# CC27x0 register map
File version: 1.0
CPU: CM4 r0p4, little endian, no MPU, no FPU, VTOR, 3 interrupt priority bits
Registers are 32-bit, read-write, reset 0x0 unless marked. A register's access mark holds for its fields unless they carry their own. Offsets are from the block's base; [hi:lo] are bit positions; {n}, {i} and the like mark numbered series; 'fields as' and 'values as' point back to an identical list.

## LRFDRFE (part 1 of 2)
Base 0x40083000
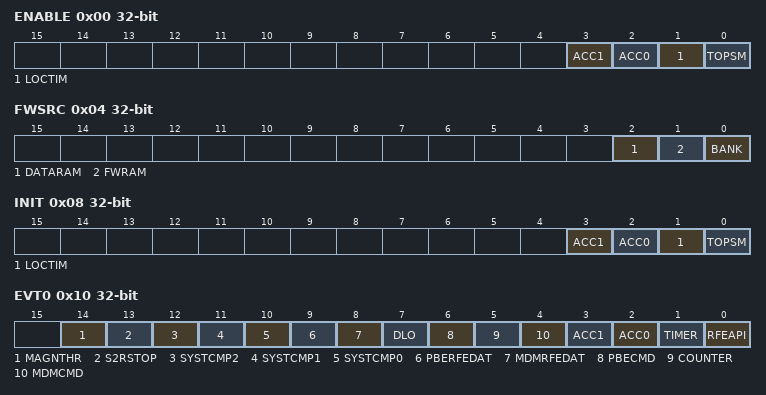
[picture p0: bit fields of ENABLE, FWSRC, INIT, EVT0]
0x00 ENABLE — Internal. Only to be used through TI provided API.
  [all] fields
    1=EN (Internal. Only to be used through TI provided API.); 0=DIS (Internal. Only to be used through TI provided API.)
  [3] ACC1 — Internal. Only to be used through TI provided API.
  [2] ACC0 — Internal. Only to be used through TI provided API.
  [1] LOCTIM — Internal. Only to be used through TI provided API.
  [0] TOPSM — Internal. Only to be used through TI provided API.
0x04 FWSRC — Internal. Only to be used through TI provided API.
  [2] DATARAM — Internal. Only to be used through TI provided API.
    1=S2RRAM (Internal. Only to be used through TI provided API.); 0=RFERAM (Internal. Only to be used through TI provided API.)
  [1] FWRAM — Internal. Only to be used through TI provided API.
    values as DATARAM
  [0] BANK — Internal. Only to be used through TI provided API.
    1=ONE (Internal. Only to be used through TI provided API.); 0=ZERO (Internal. Only to be used through TI provided API.)
0x08 INIT wo — Internal. Only to be used through TI provided API.
  [all] fields
    1=RESET (Internal. Only to be used through TI provided API.); 0=NO_EFFECT (Internal. Only to be used through TI provided API.)
  [3] ACC1 — Internal. Only to be used through TI provided API.
  [2] ACC0 — Internal. Only to be used through TI provided API.
  [1] LOCTIM — Internal. Only to be used through TI provided API.
  [0] TOPSM — Internal. Only to be used through TI provided API.
0x0C PDREQ — Internal. Only to be used through TI provided API.
  [0] TOPSMPDREQ
    values as FWSRC.BANK
0x10 EVT0 ro — Internal. Only to be used through TI provided API.
  [all] fields
    values as FWSRC.BANK
  [14] MAGNTHR — Internal. Only to be used through TI provided API.
  [13] S2RSTOP — Internal. Only to be used through TI provided API.
  [12] SYSTCMP2 — Internal. Only to be used through TI provided API.
  [11] SYSTCMP1 — Internal. Only to be used through TI provided API.
  [10] SYSTCMP0 — Internal. Only to be used through TI provided API.
  [9] PBERFEDAT — Internal. Only to be used through TI provided API.
  [8] MDMRFEDAT — Internal. Only to be used through TI provided API.
  [7] DLO — Internal. Only to be used through TI provided API.
  [6] PBECMD — Internal. Only to be used through TI provided API.
  [5] COUNTER — Internal. Only to be used through TI provided API.
  [4] MDMCMD — Internal. Only to be used through TI provided API.
  [3] ACC1 — Internal. Only to be used through TI provided API.
  [2] ACC0 — Internal. Only to be used through TI provided API.
  [1] TIMER — Internal. Only to be used through TI provided API.
  [0] RFEAPI — Internal. Only to be used through TI provided API.
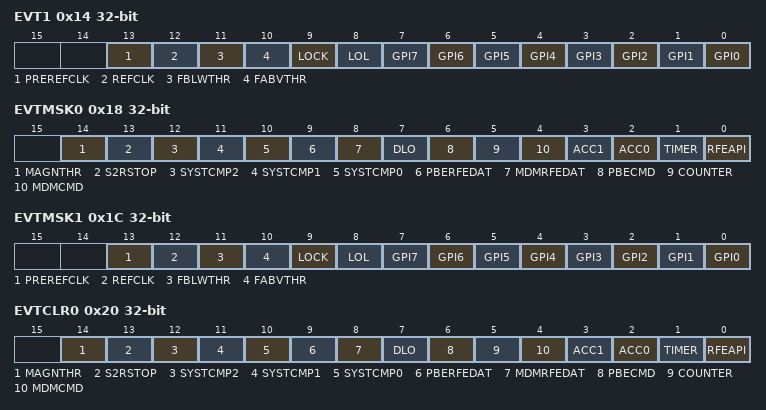
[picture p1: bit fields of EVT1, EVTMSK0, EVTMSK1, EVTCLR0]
0x14 EVT1 ro — Internal. Only to be used through TI provided API.
  [all] fields
    values as FWSRC.BANK
  [13] PREREFCLK — Internal. Only to be used through TI provided API.
  [12] REFCLK — Internal. Only to be used through TI provided API.
  [11] FBLWTHR — Internal. Only to be used through TI provided API.
  [10] FABVTHR — Internal. Only to be used through TI provided API.
  [9] LOCK — Internal. Only to be used through TI provided API.
  [8] LOL — Internal. Only to be used through TI provided API.
  [n] GPI{n} (n=0..7) — Internal. Only to be used through TI provided API.
0x18 EVTMSK0 — Internal. Only to be used through TI provided API.
  [all] fields
    values as the fields of ENABLE
  [14] MAGNTHR — Internal. Only to be used through TI provided API.
  [13] S2RSTOP — Internal. Only to be used through TI provided API.
  [12] SYSTCMP2 — Internal. Only to be used through TI provided API.
  [11] SYSTCMP1 — Internal. Only to be used through TI provided API.
  [10] SYSTCMP0 — Internal. Only to be used through TI provided API.
  [9] PBERFEDAT — Internal. Only to be used through TI provided API.
  [8] MDMRFEDAT — Internal. Only to be used through TI provided API.
  [7] DLO — Internal. Only to be used through TI provided API.
  [6] PBECMD — Internal. Only to be used through TI provided API.
  [5] COUNTER — Internal. Only to be used through TI provided API.
  [4] MDMCMD — Internal. Only to be used through TI provided API.
  [3] ACC1 — Internal. Only to be used through TI provided API.
  [2] ACC0 — Internal. Only to be used through TI provided API.
  [1] TIMER — Internal. Only to be used through TI provided API.
  [0] RFEAPI — Internal. Only to be used through TI provided API.
0x1C EVTMSK1 — Internal. Only to be used through TI provided API.
  [all] fields
    values as the fields of ENABLE
  [13] PREREFCLK — Internal. Only to be used through TI provided API.
  [12] REFCLK — Internal. Only to be used through TI provided API.
  [11] FBLWTHR — Internal. Only to be used through TI provided API.
  [10] FABVTHR — Internal. Only to be used through TI provided API.
  [9] LOCK — Internal. Only to be used through TI provided API.
  [8] LOL — Internal. Only to be used through TI provided API.
  [n] GPI{n} (n=0..7) — Internal. Only to be used through TI provided API.
0x20 EVTCLR0 wo — Internal. Only to be used through TI provided API.
  fields as EVT0
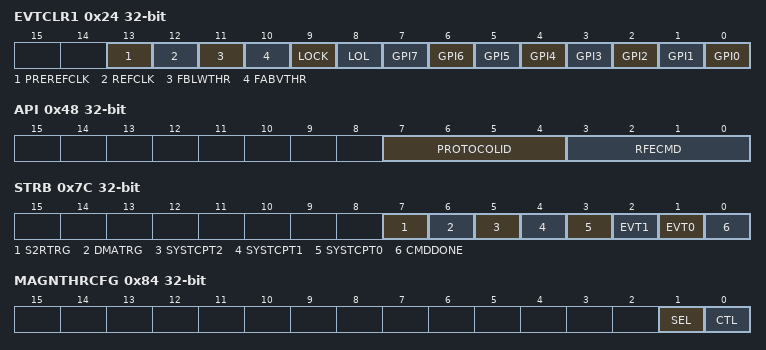
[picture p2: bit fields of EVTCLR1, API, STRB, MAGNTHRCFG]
0x24 EVTCLR1 wo — Internal. Only to be used through TI provided API.
  fields as EVT1
0x28 HFXTSTAT ro — Internal. Only to be used through TI provided API.
  [0] STAT
    1=QUAL (Internal. Only to be used through TI provided API.); 0=NONQUAL (Internal. Only to be used through TI provided API.)
0x30 RFSTATE — Internal. Only to be used through TI provided API.
  [3:0] VAL
    3=RX (Internal. Only to be used through TI provided API.); 2=TX (Internal. Only to be used through TI provided API.); 1=SYNTH (Internal. Only to be used through TI provided API.); 0=IDLE (Internal. Only to be used through TI provided API.)
0x38 SPIN ro reset 0xFF — Internal. Only to be used through TI provided API.
  [7:0] OPT
    255=ALLONES (Internal. Only to be used through TI provided API.); 0=ALLZEROS (Internal. Only to be used through TI provided API.)
0x48 API ro — Internal. Only to be used through TI provided API.
  [7:4] PROTOCOLID — Internal. Only to be used through TI provided API.
    15=ALLONES (Internal. Only to be used through TI provided API.); 0=ALLZEROS (Internal. Only to be used through TI provided API.)
  [3:0] RFECMD — Internal. Only to be used through TI provided API.
    values as PROTOCOLID
0x4C CMDPAR0 ro — Internal. Only to be used through TI provided API.
  [15:0] VAL
    0xFFFF=ALLONES (Internal. Only to be used through TI provided API.); 0=ALLZEROS (Internal. Only to be used through TI provided API.)
0x50 CMDPAR1 ro — Internal. Only to be used through TI provided API.
  fields as CMDPAR0
0x54 MSGBOX — Internal. Only to be used through TI provided API.
  [7:0] VAL
    values as SPIN.OPT
0x58 MCEDATOUT0 — Internal. Only to be used through TI provided API.
  fields as CMDPAR0
0x5C MCEDATIN0 ro — Internal. Only to be used through TI provided API.
  fields as CMDPAR0
0x60 MCECMDOUT — Internal. Only to be used through TI provided API.
  [3:0] VAL
    values as API.PROTOCOLID
0x64 MCECMDIN ro — Internal. Only to be used through TI provided API.
  fields as MCECMDOUT
0x68 PBEDATOUT1 — Internal. Only to be used through TI provided API.
  fields as CMDPAR0
0x6C PBEDATOUT0 — Internal. Only to be used through TI provided API.
  fields as CMDPAR0
0x70 PBEDATIN0 ro — Internal. Only to be used through TI provided API.
  fields as CMDPAR0
0x74 PBECMDOUT — Internal. Only to be used through TI provided API.
  fields as MCECMDOUT
0x78 PBECMDIN ro — Internal. Only to be used through TI provided API.
  fields as MCECMDOUT
0x7C STRB wo — Internal. Only to be used through TI provided API.
  [7] S2RTRG — Internal. Only to be used through TI provided API.
    values as FWSRC.BANK
  [6] DMATRG — Internal. Only to be used through TI provided API.
    values as FWSRC.BANK
  [5] SYSTCPT2 — Internal. Only to be used through TI provided API.
    values as FWSRC.BANK
  [4] SYSTCPT1 — Internal. Only to be used through TI provided API.
    values as FWSRC.BANK
  [3] SYSTCPT0 — Internal. Only to be used through TI provided API.
    values as FWSRC.BANK
  [2] EVT1 — Internal. Only to be used through TI provided API.
    values as FWSRC.BANK
  [1] EVT0 — Internal. Only to be used through TI provided API.
    values as FWSRC.BANK
  [0] CMDDONE — Internal. Only to be used through TI provided API.
    1=YES (Internal. Only to be used through TI provided API.); 0=NO (Internal. Only to be used through TI provided API.)
0x84 MAGNTHRCFG — Internal. Only to be used through TI provided API.
  [1] SEL — Internal. Only to be used through TI provided API.
    1=MAGNACC1 (Internal. Only to be used through TI provided API.); 0=MAGNACC0 (Internal. Only to be used through TI provided API.)
  [0] CTL — Internal. Only to be used through TI provided API.
    values as the fields of ENABLE
0x88 MAGNTHR — Internal. Only to be used through TI provided API.
  fields as MSGBOX
0x8C RSSIOFFSET — Internal. Only to be used through TI provided API.
  fields as MSGBOX
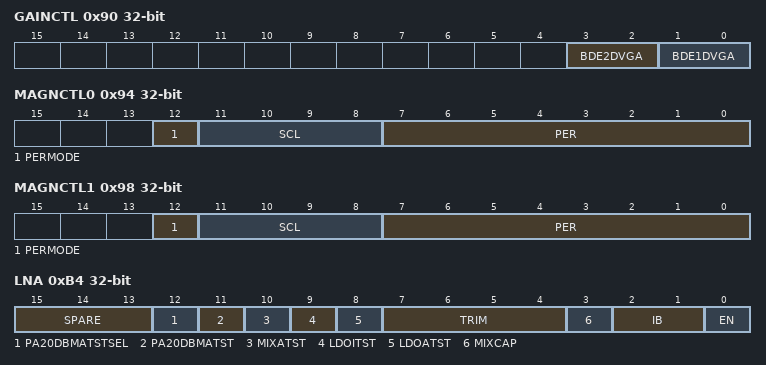
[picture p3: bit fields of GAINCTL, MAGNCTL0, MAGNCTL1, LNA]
0x90 GAINCTL — Internal. Only to be used through TI provided API.
  [3:2] BDE2DVGA — Internal. Only to be used through TI provided API.
    3=GAIN8 (Internal. Only to be used through TI provided API.); 2=GAIN4 (Internal. Only to be used through TI provided API.); 1=GAIN2 (Internal. Only to be used through TI provided API.); 0=GAIN1 (Internal. Only to be used through TI provided API.)
  [1:0] BDE1DVGA — Internal. Only to be used through TI provided API.
    values as BDE2DVGA
0x94 MAGNCTL0 — Internal. Only to be used through TI provided API.
  [12] PERMODE — Internal. Only to be used through TI provided API.
    1=PERIODIC (Internal. Only to be used through TI provided API.); 0=ONESHOT (Internal. Only to be used through TI provided API.)
  [11:8] SCL — Internal. Only to be used through TI provided API.
    8=DIV256 (Internal. Only to be used through TI provided API.); 7=DIV128 (Internal. Only to be used through TI provided API.); 6=DIV64 (Internal. Only to be used through TI provided API.); 5=DIV32 (Internal. Only to be used through TI provided API.); 4=DIV16 (Internal. Only to be used through TI provided API.); 3=DIV8 (Internal. Only to be used through TI provided API.); 2=DIV4 (Internal. Only to be used through TI provided API.); 1=DIV2 (Internal. Only to be used through TI provided API.); 0=DIV1 (Internal. Only to be used through TI provided API.)
  [7:0] PER — Internal. Only to be used through TI provided API.
    values as SPIN.OPT
0x98 MAGNCTL1 — Internal. Only to be used through TI provided API.
  fields as MAGNCTL0
{0x9C+4i} SPARE{i} (i=0..5) — Internal. Only to be used through TI provided API.
  fields as CMDPAR0
0xB4 LNA — Internal. Only to be used through TI provided API.
  [15:13] SPARE — Internal. Only to be used through TI provided API.
    values as the fields of ENABLE
  [12] PA20DBMATSTSEL — Internal. Only to be used through TI provided API.
    1=SECOND (Internal. Only to be used through TI provided API.); 0=FIRST (Internal. Only to be used through TI provided API.)
  [11] PA20DBMATST — Internal. Only to be used through TI provided API.
    values as the fields of ENABLE
  [10] MIXATST — Internal. Only to be used through TI provided API.
    values as the fields of ENABLE
  [9] LDOITST — Internal. Only to be used through TI provided API.
    values as the fields of ENABLE
  [8] LDOATST — Internal. Only to be used through TI provided API.
    values as the fields of ENABLE
  [7:4] TRIM — Internal. Only to be used through TI provided API.
    15=ONES (Internal. Only to be used through TI provided API.); 0=ZEROS (Internal. Only to be used through TI provided API.)
  [3] MIXCAP — Internal. Only to be used through TI provided API.
    values as the fields of ENABLE
  [2:1] IB — Internal. Only to be used through TI provided API.
    3=MAX (Internal. Only to be used through TI provided API.); 0=MIN (Internal. Only to be used through TI provided API.)
  [0] EN — Internal. Only to be used through TI provided API.
    1=ON (Internal. Only to be used through TI provided API.); 0=OFF (Internal. Only to be used through TI provided API.)
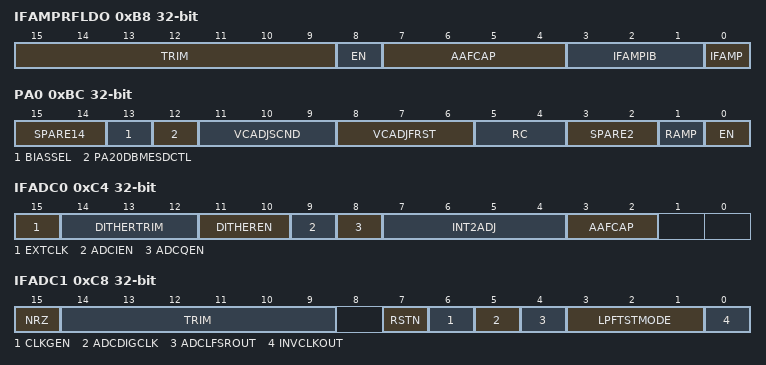
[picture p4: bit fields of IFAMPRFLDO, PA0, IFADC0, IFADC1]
0xB8 IFAMPRFLDO — Internal. Only to be used through TI provided API.
  [15:9] TRIM — Internal. Only to be used through TI provided API.
    127=BYPASS (Internal. Only to be used through TI provided API.); 126=MAX (Internal. Only to be used through TI provided API.); 0=MIN (Internal. Only to be used through TI provided API.)
  [8] EN — Internal. Only to be used through TI provided API.
    values as the fields of ENABLE
  [7:4] AAFCAP — Internal. Only to be used through TI provided API.
    15=MAX (Internal. Only to be used through TI provided API.); 0=MIN (Internal. Only to be used through TI provided API.)
  [3:1] IFAMPIB — Internal. Only to be used through TI provided API.
    7=MAX (Internal. Only to be used through TI provided API.); 0=MIN (Internal. Only to be used through TI provided API.)
  [0] IFAMP — Internal. Only to be used through TI provided API.
    values as the fields of ENABLE
0xBC PA0 — Internal. Only to be used through TI provided API.
  [15:14] SPARE14 — Internal. Only to be used through TI provided API.
    values as LNA.IB
  [13] BIASSEL — Internal. Only to be used through TI provided API.
    values as FWSRC.BANK
  [12] PA20DBMESDCTL — Internal. Only to be used through TI provided API.
    values as FWSRC.BANK
  [11:9] VCADJSCND — Internal. Only to be used through TI provided API.
    values as IFAMPRFLDO.IFAMPIB
  [8:6] VCADJFRST — Internal. Only to be used through TI provided API.
    values as IFAMPRFLDO.IFAMPIB
  [5:4] RC — Internal. Only to be used through TI provided API.
    values as LNA.IB
  [3:2] SPARE2 — Internal. Only to be used through TI provided API.
    values as LNA.IB
  [1] RAMP — Internal. Only to be used through TI provided API.
    1=UP (Internal. Only to be used through TI provided API.); 0=DOWN (Internal. Only to be used through TI provided API.)
  [0] EN — Internal. Only to be used through TI provided API.
    values as the fields of ENABLE
0xC0 ULNA — Internal. Only to be used through TI provided API.
  [15:0] SPARE
    values as CMDPAR0.VAL
0xC4 IFADC0 — Internal. Only to be used through TI provided API.
  [15] EXTCLK — Internal. Only to be used through TI provided API.
    values as the fields of ENABLE
  [14:12] DITHERTRIM — Internal. Only to be used through TI provided API.
    7=ONES (Internal. Only to be used through TI provided API.); 0=ZEROS (Internal. Only to be used through TI provided API.)
  [11:10] DITHEREN — Internal. Only to be used through TI provided API.
    3=ENG (Internal. Only to be used through TI provided API.); 2=ENSD (Internal. Only to be used through TI provided API.); 1=ENS (Internal. Only to be used through TI provided API.); 0=DIS (Internal. Only to be used through TI provided API.)
  [9] ADCIEN — Internal. Only to be used through TI provided API.
    values as the fields of ENABLE
  [8] ADCQEN — Internal. Only to be used through TI provided API.
    values as the fields of ENABLE
  [7:4] INT2ADJ — Internal. Only to be used through TI provided API.
    values as LNA.TRIM
  [3:2] AAFCAP — Internal. Only to be used through TI provided API.
    values as DITHEREN
0xC8 IFADC1 — Internal. Only to be used through TI provided API.
  [15] NRZ — Internal. Only to be used through TI provided API.
    values as the fields of ENABLE
  [14:9] TRIM — Internal. Only to be used through TI provided API.
    63=ONES (Internal. Only to be used through TI provided API.); 0=ZEROS (Internal. Only to be used through TI provided API.)
  [7] RSTN — Internal. Only to be used through TI provided API.
    1=DIS (Internal. Only to be used through TI provided API.); 0=EN (Internal. Only to be used through TI provided API.)
  [6] CLKGEN — Internal. Only to be used through TI provided API.
    values as the fields of ENABLE
  [5] ADCDIGCLK — Internal. Only to be used through TI provided API.
    values as the fields of ENABLE
  [4] ADCLFSROUT — Internal. Only to be used through TI provided API.
    values as the fields of ENABLE
  [3:1] LPFTSTMODE — Internal. Only to be used through TI provided API.
    values as the fields of ENABLE
  [0] INVCLKOUT — Internal. Only to be used through TI provided API.
    values as the fields of ENABLE
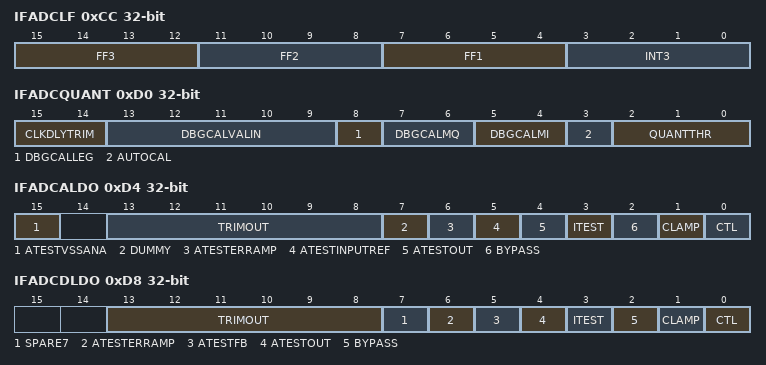
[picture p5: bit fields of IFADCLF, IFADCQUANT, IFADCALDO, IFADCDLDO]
0xCC IFADCLF — Internal. Only to be used through TI provided API.
  [all] fields
    values as LNA.TRIM
  [15:12] FF3 — Internal. Only to be used through TI provided API.
  [11:8] FF2 — Internal. Only to be used through TI provided API.
  [7:4] FF1 — Internal. Only to be used through TI provided API.
  [3:0] INT3 — Internal. Only to be used through TI provided API.
0xD0 IFADCQUANT — Internal. Only to be used through TI provided API.
  [15:14] CLKDLYTRIM — Internal. Only to be used through TI provided API.
    3=ONES (Internal. Only to be used through TI provided API.); 0=ZEROS (Internal. Only to be used through TI provided API.)
  [13:9] DBGCALVALIN — Internal. Only to be used through TI provided API.
    31=ONES (Internal. Only to be used through TI provided API.); 0=ZEROS (Internal. Only to be used through TI provided API.)
  [8] DBGCALLEG — Internal. Only to be used through TI provided API.
    1=NEG (Internal. Only to be used through TI provided API.); 0=POS (Internal. Only to be used through TI provided API.)
  [7:6] DBGCALMQ — Internal. Only to be used through TI provided API.
    3=DBGCAL_QMODB (Internal. Only to be used through TI provided API.); 2=DBGCAL_QMODP (Internal. Only to be used through TI provided API.); 1=DBGCAL_QMODN (Internal. Only to be used through TI provided API.); 0=DBGCAL_QMODZ (Internal. Only to be used through TI provided API.)
  [5:4] DBGCALMI — Internal. Only to be used through TI provided API.
    3=DBGCAL_IMODB (Internal. Only to be used through TI provided API.); 2=DBGCAL_IMODP (Internal. Only to be used through TI provided API.); 1=DBGCAL_IMODN (Internal. Only to be used through TI provided API.); 0=DBGCAL_IMODZ (Internal. Only to be used through TI provided API.)
  [3] AUTOCAL — Internal. Only to be used through TI provided API.
    values as the fields of ENABLE
  [2:0] QUANTTHR — Internal. Only to be used through TI provided API.
    values as IFADC0.DITHERTRIM
0xD4 IFADCALDO — Internal. Only to be used through TI provided API.
  [15] ATESTVSSANA — Internal. Only to be used through TI provided API.
    values as the fields of ENABLE
  [13:8] TRIMOUT — Internal. Only to be used through TI provided API.
    values as IFADC1.TRIM
  [7] DUMMY — Internal. Only to be used through TI provided API.
    1=DISN (Internal. Only to be used through TI provided API.); 0=ENN (Internal. Only to be used through TI provided API.)
  [6] ATESTERRAMP — Internal. Only to be used through TI provided API.
    values as the fields of ENABLE
  [5] ATESTINPUTREF — Internal. Only to be used through TI provided API.
    values as the fields of ENABLE
  [4] ATESTOUT — Internal. Only to be used through TI provided API.
    values as the fields of ENABLE
  [3] ITEST — Internal. Only to be used through TI provided API.
    values as the fields of ENABLE
  [2] BYPASS — Internal. Only to be used through TI provided API.
    values as the fields of ENABLE
  [1] CLAMP — Internal. Only to be used through TI provided API.
    values as the fields of ENABLE
  [0] CTL — Internal. Only to be used through TI provided API.
    values as the fields of ENABLE
0xD8 IFADCDLDO — Internal. Only to be used through TI provided API.
  [13:8] TRIMOUT — Internal. Only to be used through TI provided API.
    values as IFADC1.TRIM
  [7] SPARE7 — Internal. Only to be used through TI provided API.
    1=One (Internal. Only to be used through TI provided API.); 0=ZERO (Internal. Only to be used through TI provided API.)
  [6] ATESTERRAMP — Internal. Only to be used through TI provided API.
    values as the fields of ENABLE
  [5] ATESTFB — Internal. Only to be used through TI provided API.
    values as the fields of ENABLE
  [4] ATESTOUT — Internal. Only to be used through TI provided API.
    values as the fields of ENABLE
  [3] ITEST — Internal. Only to be used through TI provided API.
    values as the fields of ENABLE
  [2] BYPASS — Internal. Only to be used through TI provided API.
    values as the fields of ENABLE
  [1] CLAMP — Internal. Only to be used through TI provided API.
    values as the fields of ENABLE
  [0] CTL — Internal. Only to be used through TI provided API.
    values as the fields of ENABLE
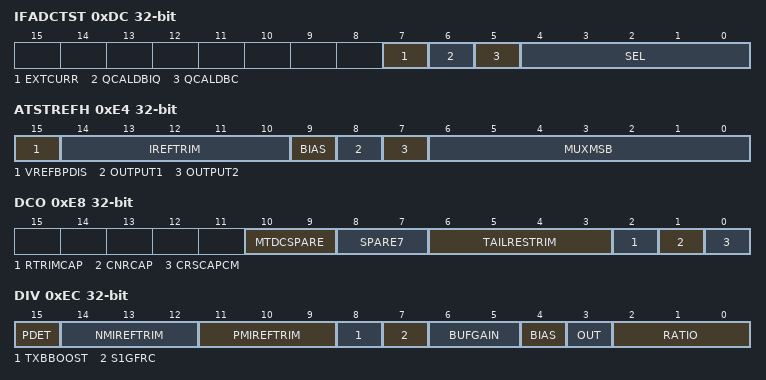
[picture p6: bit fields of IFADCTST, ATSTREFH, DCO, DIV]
0xDC IFADCTST — Internal. Only to be used through TI provided API.
  [7] EXTCURR — Internal. Only to be used through TI provided API.
    values as the fields of ENABLE
  [6] QCALDBIQ — Internal. Only to be used through TI provided API.
    1=COMP1 (Internal. Only to be used through TI provided API.); 0=COMP0 (Internal. Only to be used through TI provided API.)
  [5] QCALDBC — Internal. Only to be used through TI provided API.
    values as QCALDBIQ
  [4:0] SEL — Internal. Only to be used through TI provided API.
    31=EXTCLKN1 (Internal. Only to be used through TI provided API.); 0=NONE (Internal. Only to be used through TI provided API.)
0xE0 ATSTREFL — Internal. Only to be used through TI provided API.
  [15:0] MUXLSB
    0x8000=IFADC_ATB (Internal. Only to be used through TI provided API.); 0x4000=LDO_VTEST (Internal. Only to be used through TI provided API.); 0x2000=LDO_ITEST (Internal. Only to be used through TI provided API.); 0x800=PA_PEAK_OUTN (Internal. Only to be used through TI provided API.); 0x400=PA_PEAK_OUTP (Internal. Only to be used through TI provided API.); 0x200=MIX_OUTQN (Internal. Only to be used through TI provided API.); 0x100=MIX_OUTQP (Internal. Only to be used through TI provided API.); 128=MIX_OUTIN (Internal. Only to be used through TI provided API.); 64=MIX_OUTIP (Internal. Only to be used through TI provided API.); 32=FE_OUTIN_2 (Internal. Only to be used through TI provided API.); 16=FE_OUTIP_2 (Internal. Only to be used through TI provided API.); 8=FE_OUTQN (Internal. Only to be used through TI provided API.); 4=FE_OUTQP (Internal. Only to be used through TI provided API.); 2=FE_OUTIN (Internal. Only to be used through TI provided API.); 1=FE_OUTIP (Internal. Only to be used through TI provided API.); 0=DIS (Internal. Only to be used through TI provided API.)
0xE4 ATSTREFH — Internal. Only to be used through TI provided API.
  [15] VREFBPDIS — Internal. Only to be used through TI provided API.
    1=BPDIS (Internal. Only to be used through TI provided API.); 0=BPEN (Internal. Only to be used through TI provided API.)
  [14:10] IREFTRIM — Internal. Only to be used through TI provided API.
    values as IFADCQUANT.DBGCALVALIN
  [9] BIAS — Internal. Only to be used through TI provided API.
    values as the fields of ENABLE
  [8] OUTPUT1 — Internal. Only to be used through TI provided API.
    values as the fields of ENABLE
  [7] OUTPUT2 — Internal. Only to be used through TI provided API.
    values as the fields of ENABLE
  [6:0] MUXMSB — Internal. Only to be used through TI provided API.
    16=DIVBUF_NMOS_BIAS (Internal. Only to be used through TI provided API.); 8=DIVBUF_PMOS_BIAS (Internal. Only to be used through TI provided API.); 4=REFSYS_IREF (Internal. Only to be used through TI provided API.); 1=IFADC_ATB (Internal. Only to be used through TI provided API.); 0=DIS (Internal. Only to be used through TI provided API.)
0xE8 DCO — Internal. Only to be used through TI provided API.
  [10:9] MTDCSPARE — Internal. Only to be used through TI provided API.
    values as IFADC1.RSTN
  [8:7] SPARE7 — Internal. Only to be used through TI provided API.
    values as FWSRC.BANK
  [6:3] TAILRESTRIM — Internal. Only to be used through TI provided API.
    values as API.PROTOCOLID
  [2] RTRIMCAP — Internal. Only to be used through TI provided API.
    values as the fields of ENABLE
  [1] CNRCAP — Internal. Only to be used through TI provided API.
    1=_50MHZ (Internal. Only to be used through TI provided API.); 0=DEFAULT (Internal. Only to be used through TI provided API.)
  [0] CRSCAPCM — Internal. Only to be used through TI provided API.
    1=REDUCED (Internal. Only to be used through TI provided API.); 0=DEFAULT (Internal. Only to be used through TI provided API.)
0xEC DIV — Internal. Only to be used through TI provided API.
  [15] PDET — Internal. Only to be used through TI provided API.
    values as the fields of ENABLE
  [14:12] NMIREFTRIM — Internal. Only to be used through TI provided API.
    7=ALLONES (Internal. Only to be used through TI provided API.); 0=ALLZEROS (Internal. Only to be used through TI provided API.)
  [11:9] PMIREFTRIM — Internal. Only to be used through TI provided API.
    values as NMIREFTRIM
  [8] TXBBOOST — Internal. Only to be used through TI provided API.
    1=INCREASED (Internal. Only to be used through TI provided API.); 0=DEFAULT (Internal. Only to be used through TI provided API.)
  [7] S1GFRC — Internal. Only to be used through TI provided API.
    values as the fields of ENABLE
  [6:5] BUFGAIN — Internal. Only to be used through TI provided API.
    3=_60_PST (Internal. Only to be used through TI provided API.); 2=DONT_USE (Internal. Only to be used through TI provided API.); 1=_80_PST (Internal. Only to be used through TI provided API.); 0=MAX (Internal. Only to be used through TI provided API.)
  [4] BIAS — Internal. Only to be used through TI provided API.
    1=DEFAULT (Internal. Only to be used through TI provided API.); 0=ALTERNATIVE (Internal. Only to be used through TI provided API.)
  [3] OUT — Internal. Only to be used through TI provided API.
    1=FE_2G4 (Internal. Only to be used through TI provided API.); 0=FE_S1G (Internal. Only to be used through TI provided API.)
  [2:0] RATIO — Internal. Only to be used through TI provided API.
    7=DIV30 (Internal. Only to be used through TI provided API.); 6=DIV15 (Internal. Only to be used through TI provided API.); 5=DIV10 (Internal. Only to be used through TI provided API.); 4=DIV5 (Internal. Only to be used through TI provided API.); 3=DIV12 (Internal. Only to be used through TI provided API.); 2=DIV6 (Internal. Only to be used through TI provided API.); 1=DIV4 (Internal. Only to be used through TI provided API.); 0=DIV2 (Internal. Only to be used through TI provided API.)
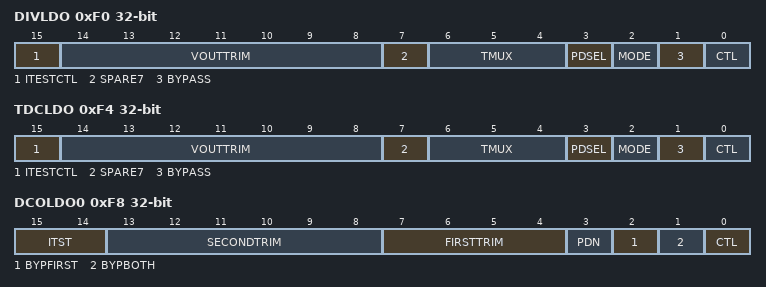
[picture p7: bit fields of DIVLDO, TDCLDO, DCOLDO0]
0xF0 DIVLDO — Internal. Only to be used through TI provided API.
  [15] ITESTCTL — Internal. Only to be used through TI provided API.
    values as the fields of ENABLE
  [14:8] VOUTTRIM — Internal. Only to be used through TI provided API.
    127=ONES (Internal. Only to be used through TI provided API.); 0=ZEROS (Internal. Only to be used through TI provided API.)
  [7] SPARE7 — Internal. Only to be used through TI provided API.
    1=ONE (Internal. Only to be used through TI provided API.); 0=Zero (Internal. Only to be used through TI provided API.)
  [6:4] TMUX — Internal. Only to be used through TI provided API.
    4=VSSR (Internal. Only to be used through TI provided API.); 2=LDO_OUT (Internal. Only to be used through TI provided API.); 1=VDDR (Internal. Only to be used through TI provided API.); 0=OFF (Internal. Only to be used through TI provided API.)
  [3] PDSEL — Internal. Only to be used through TI provided API.
    1=DIODE (Internal. Only to be used through TI provided API.); 0=R (Internal. Only to be used through TI provided API.)
  [2] MODE — Internal. Only to be used through TI provided API.
    1=FAST (Internal. Only to be used through TI provided API.); 0=NORM (Internal. Only to be used through TI provided API.)
  [1] BYPASS — Internal. Only to be used through TI provided API.
    values as the fields of ENABLE
  [0] CTL — Internal. Only to be used through TI provided API.
    values as the fields of ENABLE
0xF4 TDCLDO — Internal. Only to be used through TI provided API.
  [15] ITESTCTL — Internal. Only to be used through TI provided API.
    values as the fields of ENABLE
  [14:8] VOUTTRIM — Internal. Only to be used through TI provided API.
    values as DIVLDO.VOUTTRIM
  [7] SPARE7 — Internal. Only to be used through TI provided API.
    values as IFADCDLDO.SPARE7
  [6:4] TMUX — Internal. Only to be used through TI provided API.
    values as DIVLDO.TMUX
  [3] PDSEL — Internal. Only to be used through TI provided API.
    values as DIVLDO.PDSEL
  [2] MODE — Internal. Only to be used through TI provided API.
    values as DIVLDO.MODE
  [1] BYPASS — Internal. Only to be used through TI provided API.
    values as the fields of ENABLE
  [0] CTL — Internal. Only to be used through TI provided API.
    values as the fields of ENABLE
0xF8 DCOLDO0 — Internal. Only to be used through TI provided API.
  [15:14] ITST — Internal. Only to be used through TI provided API.
    3=BOTH (Internal. Only to be used through TI provided API.); 2=SECOND (Internal. Only to be used through TI provided API.); 1=FIRST (Internal. Only to be used through TI provided API.); 0=DIS (Internal. Only to be used through TI provided API.)
  [13:8] SECONDTRIM — Internal. Only to be used through TI provided API.
    values as IFADC1.TRIM
  [7:4] FIRSTTRIM — Internal. Only to be used through TI provided API.
    values as LNA.TRIM
  [3] PDN — Internal. Only to be used through TI provided API.
    values as the fields of ENABLE
  [2] BYPFIRST — Internal. Only to be used through TI provided API.
    values as the fields of ENABLE
  [1] BYPBOTH — Internal. Only to be used through TI provided API.
    values as the fields of ENABLE
  [0] CTL — Internal. Only to be used through TI provided API.
    values as the fields of ENABLE
